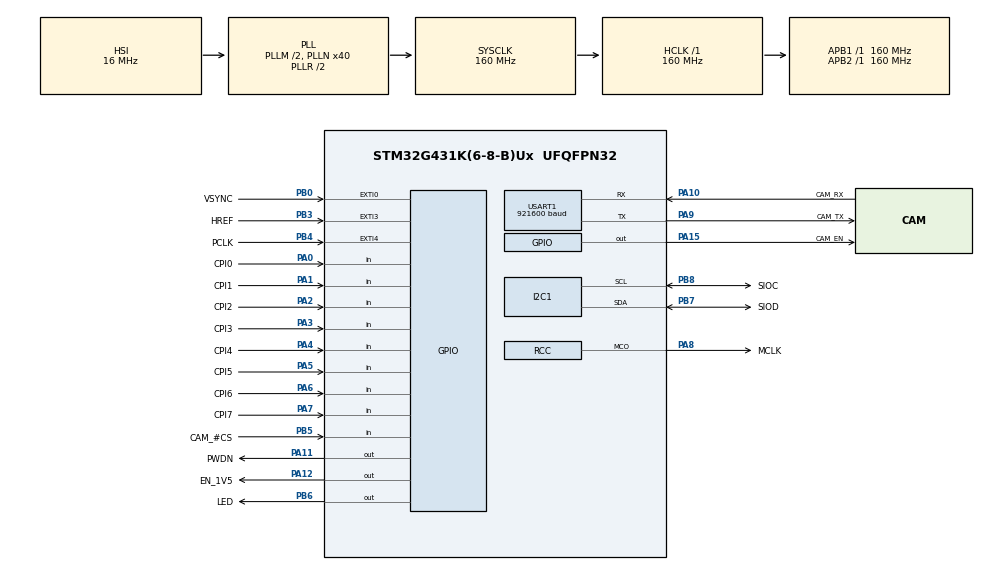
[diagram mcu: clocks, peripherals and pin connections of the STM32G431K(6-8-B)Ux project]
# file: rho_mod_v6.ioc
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Dma.DMA_GENERATOR0.0.Direction=DMA_PERIPH_TO_MEMORY
Dma.DMA_GENERATOR0.0.EventEnable=DISABLE
Dma.DMA_GENERATOR0.0.Instance=DMA1_Channel1
Dma.DMA_GENERATOR0.0.MemDataAlignment=DMA_MDATAALIGN_BYTE
Dma.DMA_GENERATOR0.0.MemInc=DMA_MINC_ENABLE
Dma.DMA_GENERATOR0.0.Mode=DMA_CIRCULAR
Dma.DMA_GENERATOR0.0.PeriphDataAlignment=DMA_PDATAALIGN_BYTE
Dma.DMA_GENERATOR0.0.PeriphInc=DMA_PINC_DISABLE
Dma.DMA_GENERATOR0.0.Polarity=HAL_DMAMUX_REQ_GEN_RISING
Dma.DMA_GENERATOR0.0.Priority=DMA_PRIORITY_LOW
Dma.DMA_GENERATOR0.0.RequestNumber=1
Dma.DMA_GENERATOR0.0.SignalID=HAL_DMAMUX1_REQ_GEN_EXTI4
Dma.DMA_GENERATOR0.0.SyncEnable=ENABLE
Dma.DMA_GENERATOR0.0.SyncPolarity=HAL_DMAMUX_SYNC_RISING
Dma.DMA_GENERATOR0.0.SyncRequestNumber=1
Dma.DMA_GENERATOR0.0.SyncSignalID=HAL_DMAMUX1_SYNC_EXTI4
Dma.Request0=DMA_GENERATOR0
I2C1.OwnAddress=0x60
I2C1.Timing=0x30909DEC
Mcu.Family=STM32G4
Mcu.Name=STM32G431K(6-8-B)Ux
Mcu.Package=UFQFPN32
NVIC.DMA1_Channel1_IRQn=true\:0\:0\:false\:false\:true\:true\:true
NVIC.DMAMUX_OVR_IRQn=true\:0\:0\:false\:false\:true\:false\:true
NVIC.EXTI0_IRQn=true\:0\:0\:false\:false\:true\:true\:true
NVIC.EXTI3_IRQn=true\:0\:0\:false\:false\:true\:true\:true
NVIC.EXTI4_IRQn=true\:0\:0\:false\:false\:true\:true\:true
NVIC.PriorityGroup=NVIC_PRIORITYGROUP_2
PA0.GPIO_Label=CPI0
PA0.Signal=GPIO_Input
PA1.GPIO_Label=CPI1
PA1.Signal=GPIO_Input
PA10.GPIO_Label=CAM_RX
PA10.Mode=Asynchronous
PA10.Signal=USART1_RX
PA11.GPIO_Label=PWDN
PA11.Signal=GPIO_Output
PA12.GPIO_Label=EN_1V5
PA12.Signal=GPIO_Output
PA13.Mode=Serial_Wire
PA13.Signal=SYS_JTMS-SWDIO
PA14.Mode=Serial_Wire
PA14.Signal=SYS_JTCK-SWCLK
PA15.GPIO_Label=CAM_EN
PA15.GPIO_PuPd=GPIO_PULLUP
PA15.Signal=GPIO_Output
PA2.GPIO_Label=CPI2
PA2.Signal=GPIO_Input
PA3.GPIO_Label=CPI3
PA3.Signal=GPIO_Input
PA4.GPIO_Label=CPI4
PA4.Signal=GPIO_Input
PA5.GPIO_Label=CPI5
PA5.Signal=GPIO_Input
PA6.GPIO_Label=CPI6
PA6.Signal=GPIO_Input
PA7.GPIO_Label=CPI7
PA7.Signal=GPIO_Input
PA8.GPIO_Label=MCLK
PA8.Mode=Clock-out
PA8.Signal=RCC_MCO
PA9.GPIO_Label=CAM_TX
PA9.Mode=Asynchronous
PA9.Signal=USART1_TX
PB0.GPIO_Label=VSYNC
PB0.Signal=GPXTI0
PB3.GPIO_Label=HREF
PB3.Signal=GPXTI3
PB4.GPIO_Label=PCLK
PB4.Signal=GPXTI4
PB5.GPIO_Label=CAM_\#CS
PB5.Signal=GPIO_Input
PB6.GPIO_Label=LED
PB6.Signal=GPIO_Output
PB7.GPIO_Label=SIOD
PB7.GPIO_Pu=GPIO_PULLUP
PB7.Mode=I2C
PB7.Signal=I2C1_SDA
PB8-BOOT0.GPIO_Label=SIOC
PB8-BOOT0.GPIO_Pu=GPIO_PULLUP
PB8-BOOT0.Mode=I2C
PB8-BOOT0.Signal=I2C1_SCL
PF0-OSC_IN.Mode=HSE-External-Oscillator
PF0-OSC_IN.Signal=RCC_OSC_IN
PF1-OSC_OUT.Mode=HSE-External-Oscillator
PF1-OSC_OUT.Signal=RCC_OSC_OUT
ProjectManager.HeapSize=0x200
ProjectManager.StackSize=0x400
ProjectManager.TargetToolchain=STM32CubeIDE
RCC.ADC12Freq_Value=160000000
RCC.AHBFreq_Value=160000000
RCC.APB1Freq_Value=160000000
RCC.APB1TimFreq_Value=160000000
RCC.APB2Freq_Value=160000000
RCC.APB2TimFreq_Value=160000000
RCC.CortexFreq_Value=160000000
RCC.EXTERNAL_CLOCK_VALUE=12288000
RCC.HCLKFreq_Value=160000000
RCC.HSE_VALUE=8000000
RCC.HSI48_VALUE=48000000
RCC.HSI_VALUE=16000000
RCC.LSE_VALUE=32768
RCC.PLLM=RCC_PLLM_DIV2
RCC.PLLN=40
RCC.RCC_MCO1Source=RCC_MCO1SOURCE_PLLCLK
RCC.RCC_MCODiv=RCC_MCODIV_8
RCC.SYSCLKFreq_VALUE=160000000
RCC.SYSCLKSource=RCC_SYSCLKSOURCE_PLLCLK
RCC.USBFreq_Value=160000000
RCC.VCOOutputFreq_Value=320000000
TIM8.Channel-Output\ Compare1\ No\ Output=TIM_CHANNEL_1
USART1.BaudRate=921600
USART1.VirtualMode-Asynchronous=VM_ASYNC
USART1.WordLength=WORDLENGTH_8B
VP_SYS_VS_DBSignals.Mode=DisableDeadBatterySignals
VP_SYS_V_PVD_IN.Mode=Mode_PVD_Int
VP_TIM8_VS_ClockSourceINT.Mode=Internal
VP_TIM8_VS_ClockSourceITR.Mode=TriggerSource_ITR0
VP_TIM8_VS_no_output1.Mode=Output Compare1 No Output
board=custom

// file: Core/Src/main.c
/* USER CODE BEGIN Header */
/**
  ******************************************************************************
  * @file           : main.c
  * @brief          : Main program body
  ******************************************************************************
  * @attention
  *
  * <h2><center>&copy; Copyright (c) 2021 STMicroelectronics.
  * All rights reserved.</center></h2>
  *
  * This software component is licensed by ST under BSD 3-Clause license,
  * the "License"; You may not use this file except in compliance with the
  * License. You may obtain a copy of the License at:
  *                        opensource.org/licenses/BSD-3-Clause
  *
  ******************************************************************************
  */
/* USER CODE END Header */
#include "main.h"

/* USER CODE BEGIN Includes */
#include "master.h"
/* USER CODE END Includes */

I2C_HandleTypeDef hi2c1;

TIM_HandleTypeDef htim8;

UART_HandleTypeDef huart1;

DMA_HandleTypeDef hdma_dma_generator0;

void SystemClock_Config(void);
static void MX_GPIO_Init(void);
static void MX_DMA_Init(void);
static void MX_I2C1_Init(void);
static void MX_TIM8_Init(void);
static void MX_USART1_UART_Init(void);

/* USER CODE BEGIN 0 */
int _write(int file, char *ptr, int len)
{
	HAL_StatusTypeDef status = HAL_UART_Transmit(&huart1, (uint8_t*)ptr, len, 1000);
	return (int)status;
}
/* USER CODE END 0 */

int main(void)
{

  /* MCU Configuration--------------------------------------------------------*/

  /* Reset of all peripherals, Initializes the Flash interface and the Systick. */
  HAL_Init();

  /* Configure the system clock */
  SystemClock_Config();

  /* Initialize all configured peripherals */
  MX_GPIO_Init();
  MX_DMA_Init();
  MX_I2C1_Init();
  MX_TIM8_Init();
  MX_USART1_UART_Init();
  /* USER CODE BEGIN 2 */
  MasterFunctions.Connect( &hi2c1, &htim8, &huart1 );
  /* USER CODE END 2 */

  /* Infinite loop */
  while (1)
  {

  }
}

void SystemClock_Config(void)
{
  RCC_OscInitTypeDef RCC_OscInitStruct = {0};
  RCC_ClkInitTypeDef RCC_ClkInitStruct = {0};
  RCC_PeriphCLKInitTypeDef PeriphClkInit = {0};

  /** Configure the main internal regulator output voltage
  */
  HAL_PWREx_ControlVoltageScaling(PWR_REGULATOR_VOLTAGE_SCALE1_BOOST);
  /** Initializes the RCC Oscillators according to the specified parameters
  * in the RCC_OscInitTypeDef structure.
  */
  RCC_OscInitStruct.OscillatorType = RCC_OSCILLATORTYPE_HSI;
  RCC_OscInitStruct.HSIState = RCC_HSI_ON;
  RCC_OscInitStruct.HSICalibrationValue = RCC_HSICALIBRATION_DEFAULT;
  RCC_OscInitStruct.PLL.PLLState = RCC_PLL_ON;
  RCC_OscInitStruct.PLL.PLLSource = RCC_PLLSOURCE_HSI;
  RCC_OscInitStruct.PLL.PLLM = RCC_PLLM_DIV2;
  RCC_OscInitStruct.PLL.PLLN = 40;
  RCC_OscInitStruct.PLL.PLLP = RCC_PLLP_DIV2;
  RCC_OscInitStruct.PLL.PLLQ = RCC_PLLQ_DIV2;
  RCC_OscInitStruct.PLL.PLLR = RCC_PLLR_DIV2;
  if (HAL_RCC_OscConfig(&RCC_OscInitStruct) != HAL_OK)
  {
    Error_Handler();
  }
  /** Initializes the CPU, AHB and APB buses clocks
  */
  RCC_ClkInitStruct.ClockType = RCC_CLOCKTYPE_HCLK|RCC_CLOCKTYPE_SYSCLK
                              |RCC_CLOCKTYPE_PCLK1|RCC_CLOCKTYPE_PCLK2;
  RCC_ClkInitStruct.SYSCLKSource = RCC_SYSCLKSOURCE_PLLCLK;
  RCC_ClkInitStruct.AHBCLKDivider = RCC_SYSCLK_DIV1;
  RCC_ClkInitStruct.APB1CLKDivider = RCC_HCLK_DIV1;
  RCC_ClkInitStruct.APB2CLKDivider = RCC_HCLK_DIV1;

  if (HAL_RCC_ClockConfig(&RCC_ClkInitStruct, FLASH_LATENCY_4) != HAL_OK)
  {
    Error_Handler();
  }
  /** Initializes the peripherals clocks
  */
  PeriphClkInit.PeriphClockSelection = RCC_PERIPHCLK_USART1|RCC_PERIPHCLK_I2C1;
  PeriphClkInit.Usart1ClockSelection = RCC_USART1CLKSOURCE_PCLK2;
  PeriphClkInit.I2c1ClockSelection = RCC_I2C1CLKSOURCE_PCLK1;
  if (HAL_RCCEx_PeriphCLKConfig(&PeriphClkInit) != HAL_OK)
  {
    Error_Handler();
  }
  HAL_RCC_MCOConfig(RCC_MCO1, RCC_MCO1SOURCE_PLLCLK, RCC_MCODIV_8);
}

static void MX_I2C1_Init(void)
{

  hi2c1.Instance = I2C1;
  hi2c1.Init.Timing = 0x30909DEC;
  hi2c1.Init.OwnAddress1 = 192;
  hi2c1.Init.AddressingMode = I2C_ADDRESSINGMODE_7BIT;
  hi2c1.Init.DualAddressMode = I2C_DUALADDRESS_DISABLE;
  hi2c1.Init.OwnAddress2 = 0;
  hi2c1.Init.OwnAddress2Masks = I2C_OA2_NOMASK;
  hi2c1.Init.GeneralCallMode = I2C_GENERALCALL_DISABLE;
  hi2c1.Init.NoStretchMode = I2C_NOSTRETCH_DISABLE;
  if (HAL_I2C_Init(&hi2c1) != HAL_OK)
  {
    Error_Handler();
  }
  /** Configure Analogue filter
  */
  if (HAL_I2CEx_ConfigAnalogFilter(&hi2c1, I2C_ANALOGFILTER_ENABLE) != HAL_OK)
  {
    Error_Handler();
  }
  /** Configure Digital filter
  */
  if (HAL_I2CEx_ConfigDigitalFilter(&hi2c1, 0) != HAL_OK)
  {
    Error_Handler();
  }

}

static void MX_TIM8_Init(void)
{

  TIM_ClockConfigTypeDef sClockSourceConfig = {0};
  TIM_SlaveConfigTypeDef sSlaveConfig = {0};
  TIM_MasterConfigTypeDef sMasterConfig = {0};
  TIM_OC_InitTypeDef sConfigOC = {0};
  TIM_BreakDeadTimeConfigTypeDef sBreakDeadTimeConfig = {0};

  htim8.Instance = TIM8;
  htim8.Init.Prescaler = 0;
  htim8.Init.CounterMode = TIM_COUNTERMODE_UP;
  htim8.Init.Period = 65535;
  htim8.Init.ClockDivision = TIM_CLOCKDIVISION_DIV1;
  htim8.Init.RepetitionCounter = 0;
  htim8.Init.AutoReloadPreload = TIM_AUTORELOAD_PRELOAD_DISABLE;
  if (HAL_TIM_Base_Init(&htim8) != HAL_OK)
  {
    Error_Handler();
  }
  sClockSourceConfig.ClockSource = TIM_CLOCKSOURCE_INTERNAL;
  if (HAL_TIM_ConfigClockSource(&htim8, &sClockSourceConfig) != HAL_OK)
  {
    Error_Handler();
  }
  if (HAL_TIM_OC_Init(&htim8) != HAL_OK)
  {
    Error_Handler();
  }
  sSlaveConfig.SlaveMode = TIM_SLAVEMODE_DISABLE;
  sSlaveConfig.InputTrigger = TIM_TS_ITR0;
  if (HAL_TIM_SlaveConfigSynchro(&htim8, &sSlaveConfig) != HAL_OK)
  {
    Error_Handler();
  }
  sMasterConfig.MasterOutputTrigger = TIM_TRGO_RESET;
  sMasterConfig.MasterOutputTrigger2 = TIM_TRGO2_RESET;
  sMasterConfig.MasterSlaveMode = TIM_MASTERSLAVEMODE_DISABLE;
  if (HAL_TIMEx_MasterConfigSynchronization(&htim8, &sMasterConfig) != HAL_OK)
  {
    Error_Handler();
  }
  sConfigOC.OCMode = TIM_OCMODE_TIMING;
  sConfigOC.Pulse = 0;
  sConfigOC.OCPolarity = TIM_OCPOLARITY_HIGH;
  sConfigOC.OCNPolarity = TIM_OCNPOLARITY_HIGH;
  sConfigOC.OCFastMode = TIM_OCFAST_DISABLE;
  sConfigOC.OCIdleState = TIM_OCIDLESTATE_RESET;
  sConfigOC.OCNIdleState = TIM_OCNIDLESTATE_RESET;
  if (HAL_TIM_OC_ConfigChannel(&htim8, &sConfigOC, TIM_CHANNEL_1) != HAL_OK)
  {
    Error_Handler();
  }
  sBreakDeadTimeConfig.OffStateRunMode = TIM_OSSR_DISABLE;
  sBreakDeadTimeConfig.OffStateIDLEMode = TIM_OSSI_DISABLE;
  sBreakDeadTimeConfig.LockLevel = TIM_LOCKLEVEL_OFF;
  sBreakDeadTimeConfig.DeadTime = 0;
  sBreakDeadTimeConfig.BreakState = TIM_BREAK_DISABLE;
  sBreakDeadTimeConfig.BreakPolarity = TIM_BREAKPOLARITY_HIGH;
  sBreakDeadTimeConfig.BreakFilter = 0;
  sBreakDeadTimeConfig.BreakAFMode = TIM_BREAK_AFMODE_INPUT;
  sBreakDeadTimeConfig.Break2State = TIM_BREAK2_DISABLE;
  sBreakDeadTimeConfig.Break2Polarity = TIM_BREAK2POLARITY_HIGH;
  sBreakDeadTimeConfig.Break2Filter = 0;
  sBreakDeadTimeConfig.Break2AFMode = TIM_BREAK_AFMODE_INPUT;
  sBreakDeadTimeConfig.AutomaticOutput = TIM_AUTOMATICOUTPUT_DISABLE;
  if (HAL_TIMEx_ConfigBreakDeadTime(&htim8, &sBreakDeadTimeConfig) != HAL_OK)
  {
    Error_Handler();
  }

}

static void MX_USART1_UART_Init(void)
{

  huart1.Instance = USART1;
  huart1.Init.BaudRate = 921600;
  huart1.Init.WordLength = UART_WORDLENGTH_8B;
  huart1.Init.StopBits = UART_STOPBITS_1;
  huart1.Init.Parity = UART_PARITY_NONE;
  huart1.Init.Mode = UART_MODE_TX_RX;
  huart1.Init.HwFlowCtl = UART_HWCONTROL_NONE;
  huart1.Init.OverSampling = UART_OVERSAMPLING_16;
  huart1.Init.OneBitSampling = UART_ONE_BIT_SAMPLE_DISABLE;
  huart1.Init.ClockPrescaler = UART_PRESCALER_DIV1;
  huart1.AdvancedInit.AdvFeatureInit = UART_ADVFEATURE_NO_INIT;
  if (HAL_UART_Init(&huart1) != HAL_OK)
  {
    Error_Handler();
  }
  if (HAL_UARTEx_SetTxFifoThreshold(&huart1, UART_TXFIFO_THRESHOLD_1_8) != HAL_OK)
  {
    Error_Handler();
  }
  if (HAL_UARTEx_SetRxFifoThreshold(&huart1, UART_RXFIFO_THRESHOLD_1_8) != HAL_OK)
  {
    Error_Handler();
  }
  if (HAL_UARTEx_DisableFifoMode(&huart1) != HAL_OK)
  {
    Error_Handler();
  }

}

static void MX_DMA_Init(void)
{

  /* Local variables */
  HAL_DMA_MuxRequestGeneratorConfigTypeDef pRequestGeneratorConfig = {0};
  HAL_DMA_MuxSyncConfigTypeDef pSyncConfig = {0};

  /* DMA controller clock enable */
  __HAL_RCC_DMAMUX1_CLK_ENABLE();
  __HAL_RCC_DMA1_CLK_ENABLE();

  /* Configure DMA request hdma_dma_generator0 on DMA1_Channel1 */
  hdma_dma_generator0.Instance = DMA1_Channel1;
  hdma_dma_generator0.Init.Request = DMA_REQUEST_GENERATOR0;
  hdma_dma_generator0.Init.Direction = DMA_PERIPH_TO_MEMORY;
  hdma_dma_generator0.Init.PeriphInc = DMA_PINC_DISABLE;
  hdma_dma_generator0.Init.MemInc = DMA_MINC_ENABLE;
  hdma_dma_generator0.Init.PeriphDataAlignment = DMA_PDATAALIGN_BYTE;
  hdma_dma_generator0.Init.MemDataAlignment = DMA_MDATAALIGN_BYTE;
  hdma_dma_generator0.Init.Mode = DMA_CIRCULAR;
  hdma_dma_generator0.Init.Priority = DMA_PRIORITY_LOW;
  if (HAL_DMA_Init(&hdma_dma_generator0) != HAL_OK)
  {
    Error_Handler( );
  }

  /* Configure the DMAMUX request generator for the selected DMA channel */
  pRequestGeneratorConfig.SignalID = HAL_DMAMUX1_REQ_GEN_EXTI4;
  pRequestGeneratorConfig.Polarity = HAL_DMAMUX_REQ_GEN_RISING;
  pRequestGeneratorConfig.RequestNumber = 1;
  if (HAL_DMAEx_ConfigMuxRequestGenerator(&hdma_dma_generator0, &pRequestGeneratorConfig) != HAL_OK)
  {
    Error_Handler( );
  }

  /* Configure the DMAMUX synchronization parameters for the selected DMA channel */
  pSyncConfig.SyncSignalID = HAL_DMAMUX1_SYNC_EXTI4;
  pSyncConfig.SyncPolarity = HAL_DMAMUX_SYNC_RISING;
  pSyncConfig.SyncEnable = ENABLE;
  pSyncConfig.EventEnable = DISABLE;
  pSyncConfig.RequestNumber = 1;
  if (HAL_DMAEx_ConfigMuxSync(&hdma_dma_generator0, &pSyncConfig) != HAL_OK)
  {
    Error_Handler( );
  }

  /* DMA interrupt init */
  /* DMA1_Channel1_IRQn interrupt configuration */
  HAL_NVIC_SetPriority(DMA1_Channel1_IRQn, 0, 0);
  HAL_NVIC_EnableIRQ(DMA1_Channel1_IRQn);
  /* DMAMUX_OVR_IRQn interrupt configuration */
  HAL_NVIC_SetPriority(DMAMUX_OVR_IRQn, 0, 0);
  HAL_NVIC_EnableIRQ(DMAMUX_OVR_IRQn);

}

static void MX_GPIO_Init(void)
{
  GPIO_InitTypeDef GPIO_InitStruct = {0};

  /* GPIO Ports Clock Enable */
  __HAL_RCC_GPIOF_CLK_ENABLE();
  __HAL_RCC_GPIOA_CLK_ENABLE();
  __HAL_RCC_GPIOB_CLK_ENABLE();

  /*Configure GPIO pin Output Level */
  HAL_GPIO_WritePin(GPIOA, PWDN_Pin|EN_1V5_Pin|CAM_EN_Pin, GPIO_PIN_RESET);

  /*Configure GPIO pin Output Level */
  HAL_GPIO_WritePin(LED_GPIO_Port, LED_Pin, GPIO_PIN_RESET);

  /*Configure GPIO pins : CPI0_Pin CPI1_Pin CPI2_Pin CPI3_Pin
                           CPI4_Pin CPI5_Pin CPI6_Pin CPI7_Pin */
  GPIO_InitStruct.Pin = CPI0_Pin|CPI1_Pin|CPI2_Pin|CPI3_Pin
                          |CPI4_Pin|CPI5_Pin|CPI6_Pin|CPI7_Pin;
  GPIO_InitStruct.Mode = GPIO_MODE_INPUT;
  GPIO_InitStruct.Pull = GPIO_NOPULL;
  HAL_GPIO_Init(GPIOA, &GPIO_InitStruct);

  /*Configure GPIO pins : VSYNC_Pin HREF_Pin PCLK_Pin */
  GPIO_InitStruct.Pin = VSYNC_Pin|HREF_Pin|PCLK_Pin;
  GPIO_InitStruct.Mode = GPIO_MODE_IT_RISING;
  GPIO_InitStruct.Pull = GPIO_NOPULL;
  HAL_GPIO_Init(GPIOB, &GPIO_InitStruct);

  /*Configure GPIO pin : MCLK_Pin */
  GPIO_InitStruct.Pin = MCLK_Pin;
  GPIO_InitStruct.Mode = GPIO_MODE_AF_PP;
  GPIO_InitStruct.Pull = GPIO_NOPULL;
  GPIO_InitStruct.Speed = GPIO_SPEED_FREQ_LOW;
  GPIO_InitStruct.Alternate = GPIO_AF0_MCO;
  HAL_GPIO_Init(MCLK_GPIO_Port, &GPIO_InitStruct);

  /*Configure GPIO pins : PWDN_Pin EN_1V5_Pin */
  GPIO_InitStruct.Pin = PWDN_Pin|EN_1V5_Pin;
  GPIO_InitStruct.Mode = GPIO_MODE_OUTPUT_PP;
  GPIO_InitStruct.Pull = GPIO_NOPULL;
  GPIO_InitStruct.Speed = GPIO_SPEED_FREQ_LOW;
  HAL_GPIO_Init(GPIOA, &GPIO_InitStruct);

  /*Configure GPIO pin : CAM_EN_Pin */
  GPIO_InitStruct.Pin = CAM_EN_Pin;
  GPIO_InitStruct.Mode = GPIO_MODE_OUTPUT_PP;
  GPIO_InitStruct.Pull = GPIO_PULLUP;
  GPIO_InitStruct.Speed = GPIO_SPEED_FREQ_LOW;
  HAL_GPIO_Init(CAM_EN_GPIO_Port, &GPIO_InitStruct);

  /*Configure GPIO pin : CAM__CS_Pin */
  GPIO_InitStruct.Pin = CAM__CS_Pin;
  GPIO_InitStruct.Mode = GPIO_MODE_INPUT;
  GPIO_InitStruct.Pull = GPIO_NOPULL;
  HAL_GPIO_Init(CAM__CS_GPIO_Port, &GPIO_InitStruct);

  /*Configure GPIO pin : LED_Pin */
  GPIO_InitStruct.Pin = LED_Pin;
  GPIO_InitStruct.Mode = GPIO_MODE_OUTPUT_PP;
  GPIO_InitStruct.Pull = GPIO_NOPULL;
  GPIO_InitStruct.Speed = GPIO_SPEED_FREQ_LOW;
  HAL_GPIO_Init(LED_GPIO_Port, &GPIO_InitStruct);

  /* EXTI interrupt init*/
  HAL_NVIC_SetPriority(EXTI0_IRQn, 0, 0);
  HAL_NVIC_EnableIRQ(EXTI0_IRQn);

  HAL_NVIC_SetPriority(EXTI3_IRQn, 0, 0);
  HAL_NVIC_EnableIRQ(EXTI3_IRQn);

  HAL_NVIC_SetPriority(EXTI4_IRQn, 0, 0);
  HAL_NVIC_EnableIRQ(EXTI4_IRQn);

}

void Error_Handler(void)
{
  __disable_irq();
  while (1)
  {
  }
}

/************************ (C) COPYRIGHT STMicroelectronics *****END OF FILE****/
